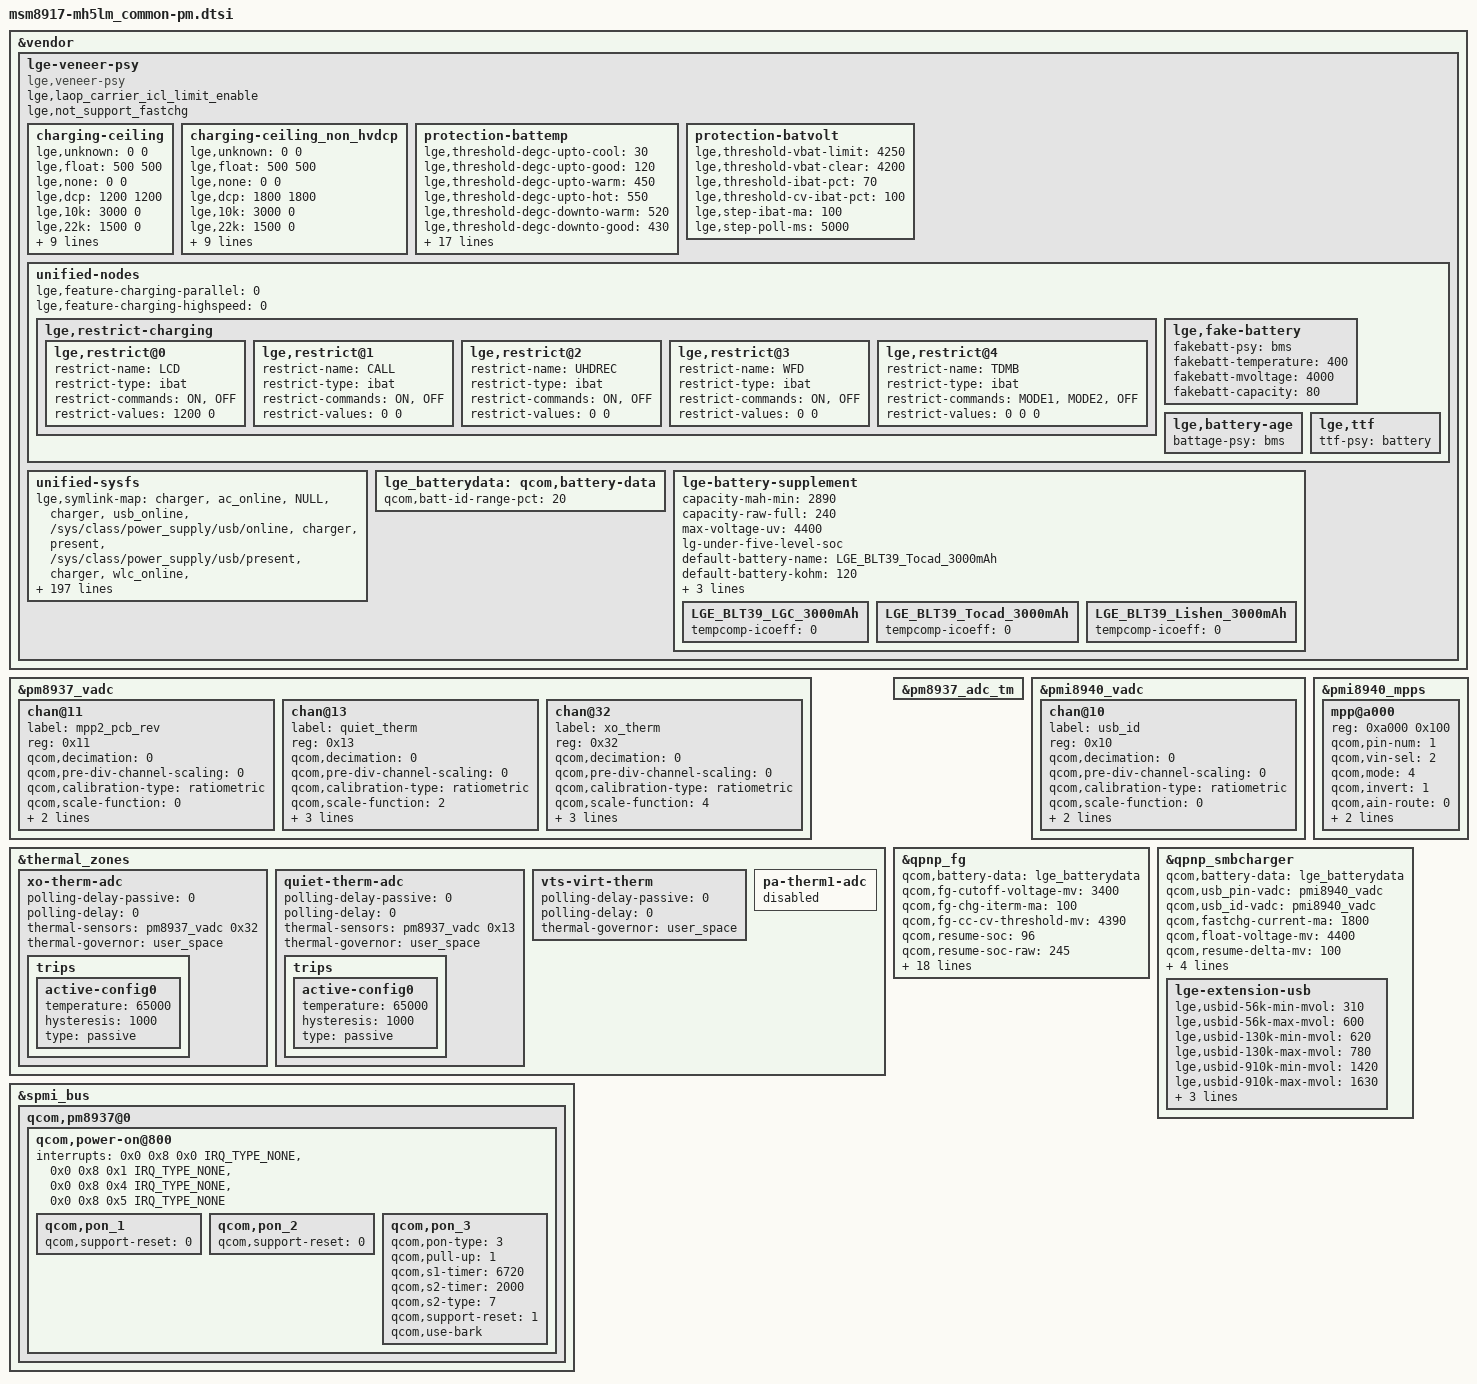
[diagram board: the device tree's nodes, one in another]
/*
 * Copyright (c) 2018, The Linux Foundation. All rights reserved.
 *
 * This program is free software; you can redistribute it and/or modify
 * it under the terms of the GNU General Public License version 2 and
 * only version 2 as published by the Free Software Foundation.
 *
 * This program is distributed in the hope that it will be useful,
 * but WITHOUT ANY WARRANTY; without even the implied warranty of
 * MERCHANTABILITY or FITNESS FOR A PARTICULAR PURPOSE.  See the
 * GNU General Public License for more details.
 */
#include <dt-bindings/thermal/thermal.h>

&vendor {
    lge-veneer-psy {
        compatible = "lge,veneer-psy";
        status = "ok";

        lge,laop_carrier_icl_limit_enable;
        lge,not_support_fastchg;
        charging-ceiling {
            /*             iusb ibat  : 0 means UNCEILING */
            lge,unknown = <   0    0>;
            lge,float   = < 500  500>;
            lge,none    = <   0    0>;

            lge,dcp     = <1200 1200>;
            lge,10k     = <3000    0>;
            lge,22k     = <1500    0>;
            lge,qc2     = <1800 3000>;
            lge,qc3     = <1800 3000>;

            lge,usb2    = < 500  500>;
            lge,usb3    = < 900  900>;
            lge,cdp     = <1200 1500>;
            lge,pd      = <   0    0>;

            lge,56k     = <1500  500>;
            lge,130k    = <1500  500>;
            lge,910k    = <1500  500>;
        };

        charging-ceiling_non_hvdcp {
            /*             iusb ibat  : 0 means UNCEILING */
            lge,unknown = <   0    0>;
            lge,float   = < 500  500>;
            lge,none    = <   0    0>;

            lge,dcp     = <1800 1800>;
            lge,10k     = <3000    0>;
            lge,22k     = <1500    0>;
            lge,qc2     = <1800 3000>;
            lge,qc3     = <1800 3000>;

            lge,usb2    = < 500  500>;
            lge,usb3    = < 900  900>;
            lge,cdp     = <1500 1500>;
            lge,pd      = <   0    0>;

            lge,56k     = <1500  500>;
            lge,130k    = <1500  500>;
            lge,910k    = <1500  500>;
        };

        protection-battemp {
            lge,threshold-degc-upto-cool = <30>;
            lge,threshold-degc-upto-good = <120>;
            lge,threshold-degc-upto-warm = <450>;
            lge,threshold-degc-upto-hot = <550>;
            lge,threshold-degc-downto-warm = <520>;
            lge,threshold-degc-downto-good = <430>;
            lge,threshold-degc-downto-cool = <100>;
            lge,threshold-degc-downto-cold = <0>;

            lge,period-ms-emergency = <10000>;
            lge,period-ms-warning   = <30000>;
            lge,period-ms-normal    = <60000>;

            // parameters for warning status cool and warm
            lge,cool-mv-alert   = <4000>;
            lge,cool-ma-alert   = <550>;        // fixed 500 mA over 4V(0.2C)   // mh5lm fixed 550mA            (0.2C)
            lge,cool-ma-pct     = <30>;         // means 0.3C rate under 4V     // mh5lm cool ibat set to 700mA (0.3C)

            lge,warm-mv-float   = <4000>;
            lge,warm-ma-pct     = <30>;         // means 0.5C rate under 4V     // mh5lm warm ibat set to 700mA (0.3C)

            // parameters for battery protection at chilly status
            lge,chilly-status-support;
            lge,chilly-degc-lowerbound = <100>;
            lge,chilly-degc-upperbound = <200>;
            lge,chilly-mv-alert    = <4000>;
	    lge,chilly-mv-bound     = <200>;
            lge,chilly-ma-alert    = <550>;    // fixed 630 mA over 4V         // mh5lm fixed 550mA             (0.2C)
            lge,chilly-ma-pct      = <40>;      // means 0.5C rate under 4V     // mh5lm chilly ibat set to 1200mA (0.4C)
        };

        protection-batvolt {
            lge,threshold-vbat-limit = <4250>;
            lge,threshold-vbat-clear = <4200>;
	    lge,threshold-ibat-pct = <70>;	// means 0.7C rate
	    lge,threshold-cv-ibat-pct = <100>;	// means 0.1C rate

            lge,step-ibat-ma = <100>;
            lge,step-poll-ms = <5000>;
        };

        unified-nodes {
            lge,feature-charging-parallel = <0>;
            lge,feature-charging-highspeed = <0>;

            lge,restrict-charging {
                // restrict-values 0 means UNCEILING

                lge,restrict@0 {
                    restrict-name = "LCD";
                    restrict-type = "ibat";
                    restrict-commands = "ON", "OFF";
                    restrict-values = <1200      0>;
                };
                lge,restrict@1 {
                    restrict-name = "CALL";
                    restrict-type = "ibat";
                    restrict-commands = "ON", "OFF";
                    restrict-values = < 0      0>;
                };
                lge,restrict@2 {
                    restrict-name = "UHDREC";
                    restrict-type = "ibat";
                    restrict-commands = "ON", "OFF";
                    restrict-values = < 0      0>;
                };
                lge,restrict@3 {
                    restrict-name = "WFD";
                    restrict-type = "ibat";
                    restrict-commands = "ON", "OFF";
                    restrict-values = < 0      0>;
                };
                lge,restrict@4 {
                    restrict-name = "TDMB";
                    restrict-type = "ibat";
                    restrict-commands = "MODE1", "MODE2", "OFF";
                    restrict-values = <    0      0      0>;
                };
            };

            lge,fake-battery {
                fakebatt-psy = "bms";       // What 'psy' does implement(or support) the fake battery?
                fakebatt-temperature = <400>;
                fakebatt-mvoltage = <4000>;
                fakebatt-capacity = <80>;
            };

            lge,battery-age {
                battage-psy = "bms";        // What 'psy' does implement(or support) the battery age?
            };

            lge,ttf {
                ttf-psy = "battery";	// What 'psy' does implement(or support) the time to full now?
            };
        };

        unified-sysfs {
            lge,symlink-map =
                /* group , user_node, kernel node */
                /* Charger */
                "charger",                     "ac_online", "NULL",
                "charger",                    "usb_online", "/sys/class/power_supply/usb/online",   /* TODO */
                "charger",                       "present", "/sys/class/power_supply/usb/present",
                "charger",                    "wlc_online", "/sys/class/power_supply/wireless/online",
                "charger",                          "type", "/sys/class/power_supply/usb/real_type",
		"charger",                   "usb_pd_type", "NULL",
                "charger",                      "time_out", "/sys/class/power_supply/battery/safety_timer_enabled",
                "charger",              "charging_enabled", "/sys/devices/platform/lge-unified-nodes/charging_enable",
                "charger",                  "ibat_current", "/sys/class/power_supply/battery/current_now",
                "charger",                  "ichg_current", "/sys/class/power_supply/usb/current_max",
                "charger",                  "iusb_control", "NULL",
                "charger",            "thermal_mitigation", "NULL",
                "charger",        "wlc_thermal_mitigation", "NULL",
                "charger",       "usb_parallel_chg_status", "NULL",
                "charger", "usb_parallel_charging_enabled", "NULL",
                "charger", "factory_parallel_charger_test", "/sys/devices/platform/lge-unified-nodes/support_fastpl",
                "charger",            "moisture_detection", "/sys/class/power_supply/usb/moisture_detected",
                "charger",           "restricted_charging", "/sys/devices/platform/lge-unified-nodes/charging_restriction",
                "charger",              "ibat_max_current", "/sys/class/power_supply/battery/constant_charge_current_max",
                "charger",                       "chgstep", "/sys/devices/platform/lge-unified-nodes/charging_step",
                "charger",               "connection_type", "NULL",
                "charger",                       "fastchg", "/sys/devices/platform/lge-unified-nodes/charger_highspeed",
                "charger",         "input_current_settled", "/sys/class/power_supply/battery/input_current_max",
                "charger",             "input_current_max", "/sys/class/power_supply/battery/input_current_max",
                "charger",            "store_demo_enabled", "NULL",
                "charger",     "wireless_charging_enabled", "NULL",
                "charger",                 "input_suspend", "/sys/class/power_supply/battery/input_suspend",
                "charger",                  "incompatible", "/sys/devices/platform/lge-unified-nodes/charger_incompatible",
                "charger",                    "hvdcp_fake", "/sys/devices/platform/lge-unified-nodes/fake_hvdcp",
                "charger",               "usb_current_max", "/sys/devices/platform/lge-unified-nodes/fake_sdpmax",
                "charger",               "fastchg_support", "/sys/devices/platform/lge-unified-nodes/support_fastchg",
                "charger",                    "usbid_type", "/sys/class/power_supply/usb/resistance_id",
                "charger",                 "ccd_batchg_en", "/sys/devices/platform/lge-unified-nodes/ccd_batchg_en",
                "charger",             "ccd_input_suspend", "/sys/devices/platform/lge-unified-nodes/ccd_input_suspend",
                "charger",                       "ccd_icl", "/sys/devices/platform/lge-unified-nodes/ccd_icl",
                "charger",                       "ccd_fcc", "/sys/devices/platform/lge-unified-nodes/ccd_fcc",
                "charger",                    "ccd_vfloat", "/sys/devices/platform/lge-unified-nodes/ccd_vfloat",
                "charger",                     "aicl_done", "/sys/devices/platform/lge-unified-nodes/aicl_done",
                /* ADC/MPP */
                "adc",              "thermal", "/sys/class/thermal/",
                "adc",             "xo_therm", "/sys/class/hwmon/hwmon2/device/xo_therm",
                "adc",           "batt_therm", "/sys/class/power_supply/battery/temp",
                "adc",              "batt_id", "/sys/devices/platform/lge-unified-nodes/battery_valid",
                "adc",            "pa_therm0", "/sys/class/hwmon/hwmon2/device/pa_therm0",
                "adc",            "pa_therm1", "NULL",
                "adc",           "quiet_therm","/sys/class/hwmon/hwmon2/device/quiet_therm",
                "adc",               "usb_in", "/sys/class/power_supply/usb/voltage_now",
                "adc",                "vcoin", "/sys/class/hwmon/hwmon2/device/vcoin",
                "adc",              "vph_pwr", "/sys/class/hwmon/hwmon2/device/vph_pwr",
                "adc",               "usb_id", "/sys/devices/platform/lge-unified-nodes/charger_usbid",
                "adc",             "usb_edge", "NULL",
                "adc",                 "pmic", "/sys/class/thermal/thermal_zone2/temp",
                "adc",                  "vts", "/sys/bus/platform/drivers/monitor-thermal/soc:lge,monitor-thermal/vts_temp",
                /* Battery */
                "battery",         "capacity", "/sys/class/power_supply/battery/capacity",
                "battery",           "health", "/sys/class/power_supply/battery/health",
                "battery",          "present", "/sys/class/power_supply/battery/present",
                "battery",      "pseudo_batt", "/sys/devices/platform/lge-unified-nodes/fake_battery",
                "battery",           "status", "/sys/class/power_supply/battery/status",
                "battery",       "status_raw", "NULL",
                "battery",             "temp", "/sys/class/power_supply/battery/temp",
                "battery",    "valid_batt_id", "/sys/devices/platform/lge-unified-nodes/battery_valid",
                "battery",      "voltage_now", "/sys/class/power_supply/battery/voltage_now",
                "battery",          "vzw_chg", "/sys/devices/platform/lge-unified-nodes/charger_verbose",
                "battery",     "raw_capacity", "/sys/class/power_supply/bms/capacity",
                "battery",        "condition", "/sys/devices/platform/lge-unified-nodes/battery_condition",
                "battery",      "battery_age", "/sys/devices/platform/lge-unified-nodes/battery_age",
                "battery","battery_age_level", "/sys/devices/platform/lge-unified-nodes/battery_age",
                "battery",            "cycle", "/sys/class/power_supply/bms/battery_cycle",
                "battery",     "battery_type", "/sys/class/power_supply/bms/battery_type",
                "battery",      "charge_full", "/sys/class/power_supply/bms/charge_full",
                "battery",   "charge_now_raw", "/sys/class/power_supply/bms/charge_now_raw",
                "battery",     "ttf_capacity", "/sys/devices/platform/lge-unified-nodes/ttf_capacity",
                "battery", "time_to_full_now", "/sys/devices/platform/lge-unified-nodes/time_to_full_now",
                /* LCD Backlight */
                "lcd",           "brightness", "/sys/class/backlight/panel0-backlight/brightness",
                "lcd",       "max_brightness", "/sys/class/backlight/panel0-backlight/max_brightness",
                "lcd_ex",        "brightness", "NULL",
                "lcd_ex",    "max_brightness", "NULL",
                /* KEY LED */
                "key_led",   "red_brightness", "/sys/class/leds/red/brightness",
                "key_led", "green_brightness", "/sys/class/leds/green/brightness",
                "key_led",  "blue_brightness", "/sys/class/leds/blue/brightness",
                "key_led",  "setting",         "/sys/class/lg_rgb_led/use_patterns/setting",
                /* CPU */
                "cpu",       "cpu_idle_modes", "NULL",
                /* GPU */
                "gpu",                 "busy", "/sys/class/kgsl/kgsl-3d0/gpubusy",
                "gpu",               "gpuclk", "/sys/class/kgsl/kgsl-3d0/gpuclk",
                /* PLATFORM */
                "platform",       "speed_bin", "NULL",
                "platform",         "pvs_bin", "NULL",
                "platform",     "power_state", "/sys/power/autosleep",
                "platform",   "poweron_alarm", "/sys/module/qpnp_rtc/parameters/poweron_alarm",
                "platform",         "pcb_rev", "/sys/class/hwmon/hwmon2/device/mpp2_pcb_rev",
                "platform",       "smpl_boot", "/sys/module/lge_smpl_count/parameters/smpl_boot",
                /* testmode */
                "testmode",            "temp", "/sys/class/power_supply/battery/temp",
                "testmode",     "voltage_now", "/sys/class/power_supply/battery/voltage_now",
                "testmode",          "usb_id", "/sys/devices/platform/lge-unified-nodes/charger_usbid",
                "testmode",         "batt_id", "/sys/devices/platform/lge-unified-nodes/battery_valid",
                "testmode",         "fuelval", "/sys/class/power_supply/battery/capacity",
                "testmode",        "xo_therm", "/sys/class/hwmon/hwmon2/device/xo_therm",
                "testmode",          "charge", "/sys/class/power_supply/battery/battery_charging_enabled",
                "testmode",          "chcomp", "/sys/devices/platform/lge-unified-nodes/charging_completed",
                "testmode",           "usbin", "/sys/class/power_supply/usb/voltage_now",
                "testmode",       "pa_therm0", "/sys/class/hwmon/hwmon2/device/pa_therm0",
                "testmode",       "pa_therm1", "NULL",
                "testmode",       "bd_therm2", "/sys/class/hwmon/hwmon2/device/quiet_therm",
                "testmode",           "vcoin", "/sys/class/hwmon/hwmon2/device/vcoin",
                "testmode",         "vph_pwr", "/sys/class/hwmon/hwmon2/device/vph_pwr",
                "testmode",     "current_now", "/sys/class/power_supply/battery/current_now",
                "testmode",     "current_max", "/sys/class/power_supply/usb/current_max",
                "testmode",         "pcb_rev", "/sys/class/hwmon/hwmon2/device/mpp2_pcb_rev",
                "testmode",      "chgmodeoff", "/sys/class/power_supply/battery/input_suspend",
                "testmode",         "fuelrst", "/sys/class/power_supply/battery/present",
                "testmode",        "rtc_time", "/dev/rtc0",
                "testmode",           "pmrst", "NULL",
                "testmode",        "battexit", "/sys/class/power_supply/battery/present",
                "testmode",  "hardreset_mode", "NULL",
                /* ps feature*/
                "psfeature",     "vfps_ratio", "/sys/class/power/vfps/vfps_ratio",
                "psfeature",           "vfps", "/sys/class/power/vfps/vfps",
                "psfeature",      "vfps_fcnt", "/sys/class/power/vfps/vfps_fcnt",
                "psfeature",  "triton_policy", "/sys/class/power/triton/cur_policy",
                "psfeature",   "cancun_is_cm", "NULL",
                "regulator",       "vreg_bob", "/sys/devices/platform/soc/soc:lrmc/bob_mode";
        };

	lge_batterydata: qcom,battery-data {
			qcom,batt-id-range-pct = <20>;
			#include "../../battery_profile/LGE_BLT39_Lishen_3000mAh.dtsi"
			#include "../../battery_profile/LGE_BLT39_LGC_3000mAh.dtsi"
			#include "../../battery_profile/LGE_BLT39_Tocad_3000mAh.dtsi"
	};


	lge-battery-supplement {
	   capacity-mah-min = <2890>;
	   capacity-raw-full = <240>;
	   max-voltage-uv = <4400>;
	   lg-under-five-level-soc;

	   default-battery-name = "LGE_BLT39_Tocad_3000mAh";
	   default-battery-kohm = <120>;

	/* format : (temp index) (temp delta) */
	   tempcomp-offset = <
	        (-300)    (-90)
	        (-200)    (-83)
	        (-190)    (-79)
	        (-180)    (-74)
	        (-170)    (-68)
	        (-160)    (-62)
	        (-150)    (-54)
	        (-100)    (-22)
	        ( -50)    (-15)
	        0         (-12)
	        50        (-10)
	        100       (-7)
	        150       (-10)
	        200       (-12)
	        250       (-12)
	        300       (-12)
	        350       (-15)
	        400       (-15)
	        450       (-15)
	        500       (-12)
	        550       (-5)
	        600       (-2)
	        700       0
	        800       0
	        900     0
	        >;
	   tempcomp-icoeff = <0>;
//	   tempcomp-qnovo-charging;

	/* overriding by battery type */
		LGE_BLT39_LGC_3000mAh {
	        tempcomp-icoeff = <0>;
	        };
		LGE_BLT39_Tocad_3000mAh {
	        tempcomp-icoeff = <0>;
	        };
		LGE_BLT39_Lishen_3000mAh {
	        tempcomp-icoeff = <0>;
	        };
	};
    };
};

&pm8937_vadc {
	chan@11 {
		label = "mpp2_pcb_rev";
		reg = <0x11>;
		qcom,decimation = <0>;
		qcom,pre-div-channel-scaling = <0>;
		qcom,calibration-type = "ratiometric";
		qcom,scale-function = <0>;
		qcom,hw-settle-time = <2>;
		qcom,fast-avg-setup = <3>;
	};

	chan@13 {
		label = "quiet_therm";
		reg = <0x13>;
		qcom,decimation = <0>;
		qcom,pre-div-channel-scaling = <0>;
		qcom,calibration-type = "ratiometric";
		qcom,scale-function = <2>;
		qcom,hw-settle-time = <2>;
		qcom,fast-avg-setup = <0>;
		qcom,vadc-thermal-node;
	};

	chan@32 {
		label = "xo_therm";
		reg = <0x32>;
		qcom,decimation = <0>;
		qcom,pre-div-channel-scaling = <0>;
		qcom,calibration-type = "ratiometric";
		qcom,scale-function = <4>;
		qcom,hw-settle-time = <2>;
		qcom,fast-avg-setup = <0>;
		qcom,vadc-thermal-node;
	};
};

&thermal_zones {
	xo-therm-adc {
		polling-delay-passive = <0>;
		polling-delay = <0>;
		thermal-sensors = <&pm8937_vadc 0x32>;
		thermal-governor = "user_space";

		trips {
			active-config0 {
				temperature = <65000>;
				hysteresis = <1000>;
				type = "passive";
			};
		};
	};

	quiet-therm-adc {
		polling-delay-passive = <0>;
		polling-delay = <0>;
		thermal-sensors = <&pm8937_vadc 0x13>;
		thermal-governor = "user_space";

		trips {
			active-config0 {
				temperature = <65000>;
				hysteresis = <1000>;
				type = "passive";
			};
		};
	};

	vts-virt-therm {
		polling-delay-passive = <0>;
		polling-delay = <0>;
		thermal-governor = "user_space";
	};

	pa-therm1-adc {
		status = "disabled";
	};
};

&pm8937_adc_tm {
	#thermal-sensor-cells = <1>;
};

&pmi8940_vadc {
        chan@10 {
                        label = "usb_id";
                        reg = <0x10>;
                        qcom,decimation = <0>;
                        qcom,pre-div-channel-scaling = <0>;
                        qcom,calibration-type = "ratiometric";
                        qcom,scale-function = <0>;
                        qcom,hw-settle-time = <2>;
                        qcom,fast-avg-setup = <0>;
                };
};

&pmi8940_mpps {
        mpp@a000 {
                        reg = <0xa000 0x100>;
                        qcom,pin-num = <1>;
                        status = "okay";
                        qcom,vin-sel = <2>;
                        qcom,mode = <4>; /* AIN input */
                        qcom,invert = <1>; /* Enable MPP */
                        qcom,ain-route = <0>; /* AMUX 5 */
                        qcom,master-en = <1>;
                        qcom,src-sel = <0>; /* Function constant */
                };
};

&qpnp_fg {
	qcom,battery-data = <&lge_batterydata>;
	qcom,fg-cutoff-voltage-mv = <3400>;
	qcom,fg-chg-iterm-ma = <100>;
	qcom,fg-cc-cv-threshold-mv = <4390>;
	qcom,resume-soc = <96>;
	qcom,resume-soc-raw = <245>;
        qcom,thermal-coefficients = [D2 85 0E 4A A5 35];
	qcom,ext-sense-type;
	qcom,capacity-learning-feedback;
	qcom,fg-iterm-ma = <200>;
	qcom,vbat-estimate-diff-mv = <250>;
	qcom,esr-pulse-tuning-en;
	qcom,fg-use-vbat-low-empty-soc;
	qcom,fg-cc-soc-limit-pct = <120>;
	qcom,fg-control-slope-limiter;
	qcom,fg-slope-limit-high-temp-chg = <6>;
	qcom,fg-slope-limit-high-temp-dischg = <6>;
	qcom,fg-slope-limit-low-temp-chg = <14>;
	qcom,fg-slope-limit-low-temp-dischg =<14>;
	qcom,fg-dischg-voltage-gain-ctrl;
	qcom,fg-dischg-voltage-gain-soc = <7 15 20>;
	qcom,fg-dischg-med-voltage-gain = <5 4 4>;
	qcom,fg-dischg-high-voltage-gain = <5 5 4>;
	qcom,cl-max-limit-deciperc= <50>;
};

&qpnp_smbcharger {
	qcom,battery-data = <&lge_batterydata>;
        qcom,usb_pin-vadc = <&pmi8940_vadc>;
	qcom,usb_id-vadc = <&pmi8940_vadc>;
	qcom,fastchg-current-ma = <1800>;
	qcom,float-voltage-mv = <4400>;
	qcom,resume-delta-mv = <100>;
	qcom,iterm-ma = <100>;
	qcom,bmd-pin-src = "bpd_none";
	lge,hvdcp-not-supported;
	lge,jeita-disabled;
	lge-extension-usb {
		lge,usbid-56k-min-mvol = <310>;
		lge,usbid-56k-max-mvol = <600>;
		lge,usbid-130k-min-mvol = <620>;
		lge,usbid-130k-max-mvol = <780>;
		lge,usbid-910k-min-mvol = <1420>;
		lge,usbid-910k-max-mvol = <1630>;
		lge,usbid-open-min-mvol = <1631>;
		lge,usbid-open-max-mvol = <1900>;
		lge,feature-moisture-charging = <0>;
	};
};

&spmi_bus {
	qcom,pm8937@0 {
		qcom,power-on@800 {
			interrupts = <0x0 0x8 0x0 IRQ_TYPE_NONE>,
				     <0x0 0x8 0x1 IRQ_TYPE_NONE>,
				     <0x0 0x8 0x4 IRQ_TYPE_NONE>,
				     <0x0 0x8 0x5 IRQ_TYPE_NONE>;
			interrupt-names = "kpdpwr", "resin",
				"resin-bark", "kpdpwr-resin-bark";

			qcom,pon_1 {
				status = "ok";
				qcom,support-reset = <0>;
			};
			qcom,pon_2 {
				status = "ok";
				qcom,support-reset = <0>;
			};
			qcom,pon_3 {
				status = "ok";
				qcom,pon-type = <3>;
				qcom,pull-up = <1>;
				qcom,s1-timer = <6720>;
				qcom,s2-timer = <2000>;
				qcom,s2-type = <7>;
				qcom,support-reset = <1>;
				qcom,use-bark;
			};
		};
	};
};
